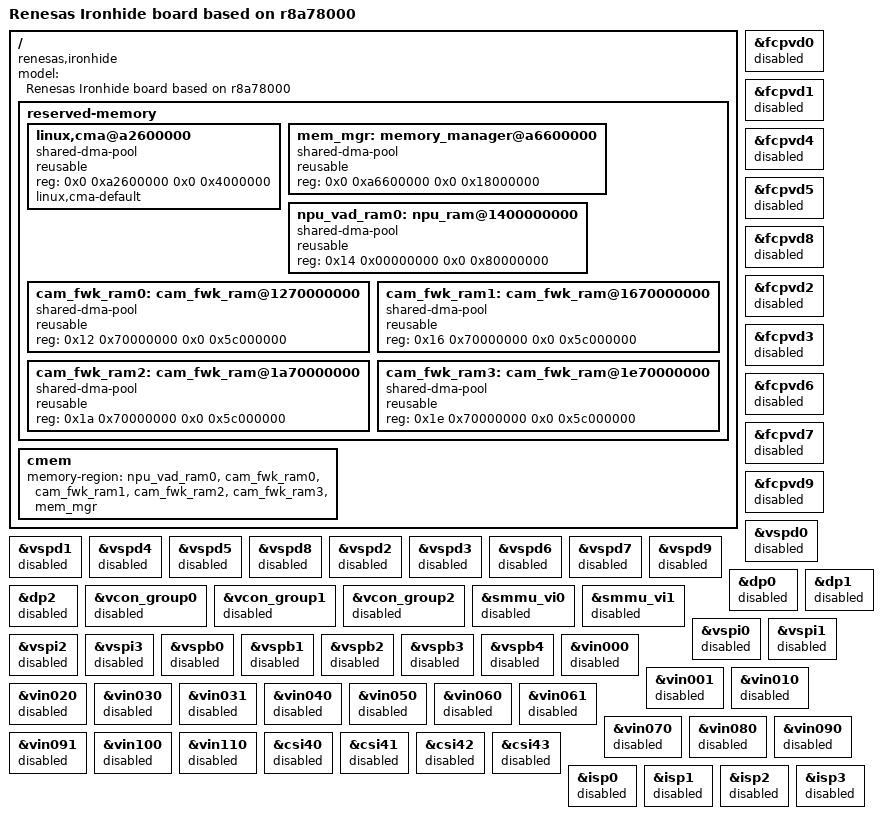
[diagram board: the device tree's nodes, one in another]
// SPDX-License-Identifier: (GPL-2.0-only OR BSD-2-Clause)
/*
 * Device Tree Source fragment for UIO support on the R-Car X5H (R8A78000) SoC
 *
 * Copyright (C) 2025 Renesas Electronics Corp.
 */

/dts-v1/;
#include "r8a78000-uio.dtsi"
#include "r8a78000-ironhide-common.dtsi"

/ {
	model = "Renesas Ironhide board based on r8a78000";
	compatible = "renesas,ironhide", "renesas,r8a78000", "renesas,r8a78000-uio";

	reserved-memory {
		#address-cells = <2>;
		#size-cells = <2>;
		ranges;

		/delete-node/ linux,cma@a2600000;

		linux,cma@a2600000 {
			compatible = "shared-dma-pool";
			reusable;
			reg = <0x0 0xa2600000 0x0 0x4000000>;
			linux,cma-default;
		};

		mem_mgr: memory_manager@a6600000 {
			compatible = "shared-dma-pool";
			reusable;
			reg = <0x0 0xa6600000 0x0 0x18000000>;
		};

		npu_vad_ram0: npu_ram@1400000000 {
			compatible = "shared-dma-pool";
			reusable;
			reg = <0x14 0x00000000 0x0 0x80000000>;
		};

		cam_fwk_ram0: cam_fwk_ram@1270000000 {
			compatible = "shared-dma-pool";
			reusable;
			reg = <0x12 0x70000000 0x0 0x5c000000 >;
		};

		cam_fwk_ram1: cam_fwk_ram@1670000000 {
			compatible = "shared-dma-pool";
			reusable;
			reg = <0x16 0x70000000 0x0 0x5c000000 >;
		};

		cam_fwk_ram2: cam_fwk_ram@1a70000000 {
			compatible = "shared-dma-pool";
			reusable;
			reg = <0x1a 0x70000000 0x0 0x5c000000 >;
		};

		cam_fwk_ram3: cam_fwk_ram@1e70000000 {
			compatible = "shared-dma-pool";
			reusable;
			reg = <0x1e 0x70000000 0x0 0x5c000000 >;
		};
	};

	cmem {
		memory-region = <&npu_vad_ram0>,
				<&cam_fwk_ram0>, <&cam_fwk_ram1>,
				<&cam_fwk_ram2>, <&cam_fwk_ram3>,
				<&mem_mgr>;
	};
};

&fcpvd0 {
	status = "disabled";
};

&fcpvd1 {
	status = "disabled";
};

&fcpvd4 {
	status = "disabled";
};

&fcpvd5 {
	status = "disabled";
};

&fcpvd8 {
	status = "disabled";
};

&fcpvd2 {
	status = "disabled";
};

&fcpvd3 {
	status = "disabled";
};

&fcpvd6 {
	status = "disabled";
};

&fcpvd7 {
	status = "disabled";
};

&fcpvd9 {
	status = "disabled";
};

&vspd0 {
	status = "disabled";
};

&vspd1 {
	status = "disabled";
};

&vspd4 {
	status = "disabled";
};

&vspd5 {
	status = "disabled";
};

&vspd8 {
	status = "disabled";
};

&vspd2 {
	status = "disabled";
};

&vspd3 {
	status = "disabled";
};

&vspd6 {
	status = "disabled";
};

&vspd7 {
	status = "disabled";
};

&vspd9 {
	status = "disabled";
};

&dp0 {
	status = "disabled";
};

&dp1 {
	status = "disabled";
};

&dp2 {
	status = "disabled";
};

&vcon_group0 {
	status = "disabled";
};

&vcon_group1 {
	status = "disabled";
};

&vcon_group2 {
	status = "disabled";
};

&smmu_vi0 {
	status = "disabled";
};

&smmu_vi1 {
	status = "disabled";
};

&vspi0 {
	status = "disabled";
};

&vspi1 {
	status = "disabled";
};

&vspi2 {
	status = "disabled";
};

&vspi3 {
	status = "disabled";
};

&vspb0 {
	status = "disabled";
};

&vspb1 {
	status = "disabled";
};

&vspb2 {
	status = "disabled";
};

&vspb3 {
	status = "disabled";
};

&vspb4 {
	status = "disabled";
};

&vin000 {
	status = "disabled";
};

&vin001 {
	status = "disabled";
};

&vin010 {
	status = "disabled";
};

&vin020 {
	status = "disabled";
};

&vin030 {
	status = "disabled";
};

&vin031 {
	status = "disabled";
};

&vin040 {
	status = "disabled";
};

&vin050 {
	status = "disabled";
};

&vin060 {
	status = "disabled";
};

&vin061 {
	status = "disabled";
};

&vin070 {
	status = "disabled";
};

&vin080 {
	status = "disabled";
};

&vin090 {
	status = "disabled";
};

&vin091 {
	status = "disabled";
};

&vin100 {
	status = "disabled";
};

&vin110 {
	status = "disabled";
};

&csi40 {
	status = "disabled";
};

&csi41 {
	status = "disabled";
};

&csi42 {
	status = "disabled";
};

&csi43 {
	status = "disabled";
};

&isp0 {
	status = "disabled";
};

&isp1 {
	status = "disabled";
};

&isp2 {
	status = "disabled";
};

&isp3 {
	status = "disabled";
};
